# nrf52840 register map
Vendor: Nordic Semiconductor; Series: nrf52; File version: 1
CPU: CM4 r0p1, little endian, MPU, FPU, 3 interrupt priority bits
Registers are 32-bit, read-write, reset 0x0 unless marked. A register's access mark holds for its fields unless they carry their own. Offsets are from the block's base; [hi:lo] are bit positions; 'fields as' and 'values as' point back to an identical list.

## CLOCK — Clock control
Base 0x40000000
0x00 TASKS_HFCLKSTART wo — Start HFXO crystal oscillator
  [0] TASKS_HFCLKSTART
0x04 TASKS_HFCLKSTOP wo — Stop HFXO crystal oscillator
  [0] TASKS_HFCLKSTOP
0x08 TASKS_LFCLKSTART wo — Start LFCLK
  [0] TASKS_LFCLKSTART
0x0C TASKS_LFCLKSTOP wo — Stop LFCLK
  [0] TASKS_LFCLKSTOP
0x10 TASKS_CAL wo — Start calibration of LFRC
  [0] TASKS_CAL
0x14 TASKS_CTSTART wo — Start calibration timer
  [0] TASKS_CTSTART
0x18 TASKS_CTSTOP wo — Stop calibration timer
  [0] TASKS_CTSTOP
0x100 EVENTS_HFCLKSTARTED — HFXO crystal oscillator started
  [0] EVENTS_HFCLKSTARTED
0x104 EVENTS_LFCLKSTARTED — LFCLK started
  [0] EVENTS_LFCLKSTARTED
0x10C EVENTS_DONE — Calibration of LFRC completed
  [0] EVENTS_DONE
0x110 EVENTS_CTTO — Calibration timer timeout
  [0] EVENTS_CTTO
0x128 EVENTS_CTSTARTED — Calibration timer has been started and is ready to process new tasks
  [0] EVENTS_CTSTARTED
0x12C EVENTS_CTSTOPPED — Calibration timer has been stopped and is ready to process new tasks
  [0] EVENTS_CTSTOPPED
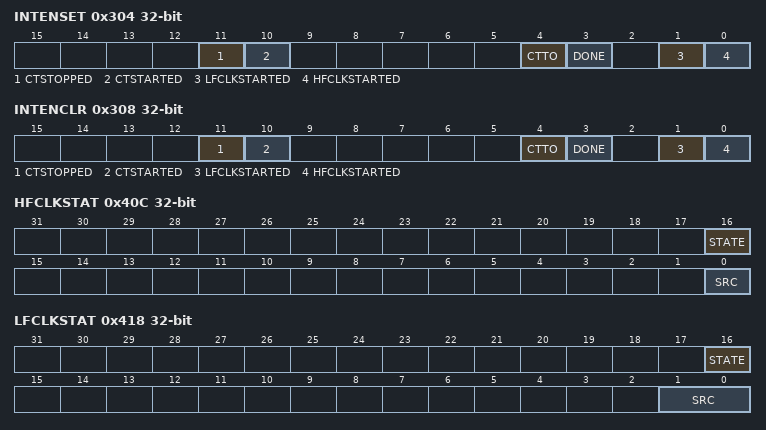
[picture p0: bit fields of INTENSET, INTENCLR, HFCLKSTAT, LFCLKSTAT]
0x304 INTENSET — Enable interrupt
  [all] fields
    on read: 0=Disabled (Read: Disabled); 1=Enabled (Read: Enabled) | on write: 1=Set (Enable)
  [11] CTSTOPPED — Write '1' to enable interrupt for CTSTOPPED event
  [10] CTSTARTED — Write '1' to enable interrupt for CTSTARTED event
  [4] CTTO — Write '1' to enable interrupt for CTTO event
  [3] DONE — Write '1' to enable interrupt for DONE event
  [1] LFCLKSTARTED — Write '1' to enable interrupt for LFCLKSTARTED event
  [0] HFCLKSTARTED — Write '1' to enable interrupt for HFCLKSTARTED event
0x308 INTENCLR — Disable interrupt
  [all] fields
    on read: 0=Disabled (Read: Disabled); 1=Enabled (Read: Enabled) | on write: 1=Clear (Disable)
  [11] CTSTOPPED — Write '1' to disable interrupt for CTSTOPPED event
  [10] CTSTARTED — Write '1' to disable interrupt for CTSTARTED event
  [4] CTTO — Write '1' to disable interrupt for CTTO event
  [3] DONE — Write '1' to disable interrupt for DONE event
  [1] LFCLKSTARTED — Write '1' to disable interrupt for LFCLKSTARTED event
  [0] HFCLKSTARTED — Write '1' to disable interrupt for HFCLKSTARTED event
0x408 HFCLKRUN ro — Status indicating that HFCLKSTART task has been triggered
  [0] STATUS — HFCLKSTART task triggered or not
    0=NotTriggered (Task not triggered); 1=Triggered (Task triggered)
0x40C HFCLKSTAT ro — HFCLK status
  [16] STATE — HFCLK state
    0=NotRunning (HFCLK not running); 1=Running (HFCLK running)
  [0] SRC — Source of HFCLK
    0=RC (64 MHz internal oscillator (HFINT)); 1=Xtal (64 MHz crystal oscillator (HFXO))
0x414 LFCLKRUN ro — Status indicating that LFCLKSTART task has been triggered
  [0] STATUS — LFCLKSTART task triggered or not
    values as HFCLKRUN.STATUS
0x418 LFCLKSTAT ro — LFCLK status
  [16] STATE — LFCLK state
    0=NotRunning (LFCLK not running); 1=Running (LFCLK running)
  [1:0] SRC — Source of LFCLK
    0=RC (32.768 kHz RC oscillator (LFRC)); 1=Xtal (32.768 kHz crystal oscillator (LFXO)); 2=Synth (32.768 kHz synthesized from HFCLK (LFSYNT))
0x41C LFCLKSRCCOPY ro — Copy of LFCLKSRC register, set when LFCLKSTART task was triggered
  [1:0] SRC — Clock source
    values as LFCLKSTAT.SRC
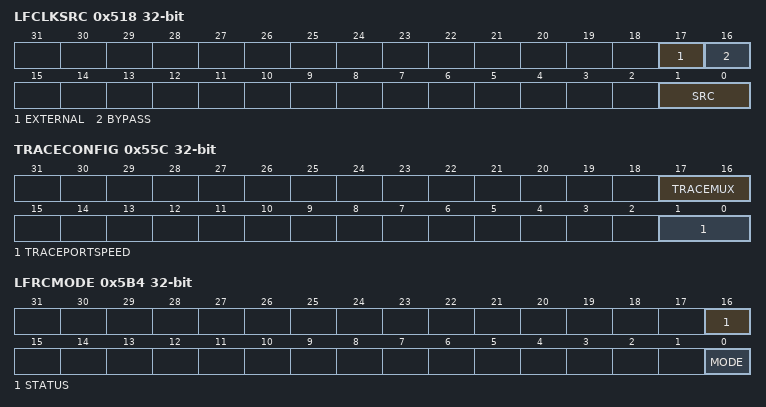
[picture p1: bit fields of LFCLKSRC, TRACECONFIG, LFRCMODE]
0x518 LFCLKSRC — Clock source for the LFCLK
  [17] EXTERNAL — Enable or disable external source for LFCLK
    0=Disabled (Disable external source (use with Xtal)); 1=Enabled (Enable use of external source instead of Xtal (SRC needs to be set to Xtal))
  [16] BYPASS — Enable or disable bypass of LFCLK crystal oscillator with external clock source
    0=Disabled (Disable (use with Xtal or low-swing external source)); 1=Enabled (Enable (use with rail-to-rail external source))
  [1:0] SRC — Clock source
    values as LFCLKSTAT.SRC
0x528 HFXODEBOUNCE reset 0x10 — HFXO debounce time. The HFXO is started by triggering the TASKS_HFCLKSTART task.
  [7:0] HFXODEBOUNCE — HFXO debounce time. Debounce time = HFXODEBOUNCE * 16 us.
    16=Db256us (256 us debounce time. Recommended for TSX-3225, FA-20H and FA-128 crystals.); 64=Db1024us (1024 us debounce time. Recommended for NX1612AA and NX1210AB crystals.)
0x538 CTIV — Calibration timer interval
  [6:0] CTIV — Calibration timer interval in multiple of 0.25 seconds. Range: 0.25 seconds to 31.75 seconds.
0x55C TRACECONFIG — Clocking options for the trace port debug interface
  [17:16] TRACEMUX — Pin multiplexing of trace signals. See pin assignment chapter for more details.
    0=GPIO (No trace signals routed to pins. All pins can be used as regular GPIOs.); 1=Serial (SWO trace signal routed to pin. Remaining pins can be used as regular GPIOs.); 2=Parallel (All trace signals (TRACECLK and TRACEDATA[n]) routed to pins.)
  [1:0] TRACEPORTSPEED — Speed of trace port clock. Note that the TRACECLK pin will output this clock divided by two.
    0=32 MHz trace port clock (TRACECLK = 16 MHz); 1=16 MHz trace port clock (TRACECLK = 8 MHz); 2=8 MHz trace port clock (TRACECLK = 4 MHz); 3=4 MHz trace port clock (TRACECLK = 2 MHz)
0x5B4 LFRCMODE — LFRC mode configuration
  [16] STATUS — Active LFRC mode. This field is read only.
    0=Normal mode; 1=ULP (Ultra-low power mode (ULP))
  [0] MODE — Set LFRC mode
    0=Normal mode; 1=ULP (Ultra-low power mode (ULP))
